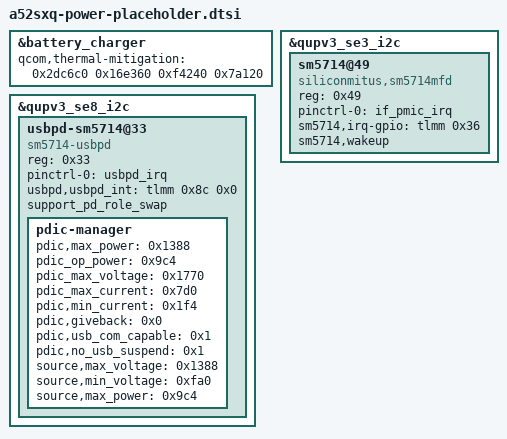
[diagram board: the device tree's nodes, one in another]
// SPDX-License-Identifier: GPL-2.0
/*
 * a52sxq board description for the Qualcomm 6.12 yupik base: power (owned by agent 'power': TODO-binding placeholder)
 * GENERATED by tools/gen.py from the phone's stock dtbo (5.4 bindings, values verbatim).
 * Do not edit: hand-written 6.12 changes live in a52sxq-bsp612-fixups.dtsi.
 */

&battery_charger {
	#cooling-cells = <0x2>;
	qcom,thermal-mitigation = <0x2dc6c0 0x16e360 0xf4240 0x7a120>;
};

&qupv3_se3_i2c {

	sm5714@49 {
		status = "okay";
		compatible = "siliconmitus,sm5714mfd";
		reg = <0x49>;
		pinctrl-names = "default";
		pinctrl-0 = <&if_pmic_irq>;
		sm5714,irq-gpio = <&tlmm 0x36 0x0>;
		sm5714,wakeup;
	};
};

&qupv3_se8_i2c {

	usbpd-sm5714@33 {
		status = "okay";
		compatible = "sm5714-usbpd";
		reg = <0x33>;
		pinctrl-names = "default";
		pinctrl-0 = <&usbpd_irq>;
		usbpd,usbpd_int = <&tlmm 0x8c 0x0>;
		support_pd_role_swap;

		pdic-manager {
			pdic,max_power = <0x1388>;
			pdic_op_power = <0x9c4>;
			pdic_max_voltage = <0x1770>;
			pdic_max_current = <0x7d0>;
			pdic,min_current = <0x1f4>;
			pdic,giveback = <0x0>;
			pdic,usb_com_capable = <0x1>;
			pdic,no_usb_suspend = <0x1>;
			source,max_voltage = <0x1388>;
			source,min_voltage = <0xfa0>;
			source,max_power = <0x9c4>;
		};
	};
};

